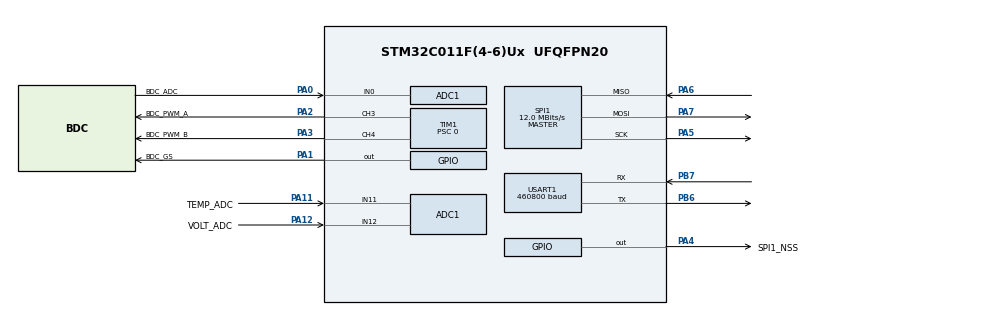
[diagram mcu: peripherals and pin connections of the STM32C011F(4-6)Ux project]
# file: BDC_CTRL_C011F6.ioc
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ADC1.Channel-0\#ChannelRegularConversion=ADC_CHANNEL_0
ADC1.Channel-1\#ChannelRegularConversion=ADC_CHANNEL_11
ADC1.Channel-2\#ChannelRegularConversion=ADC_CHANNEL_12
ADC1.ClockPrescaler=ADC_CLOCK_SYNC_PCLK_DIV2
ADC1.ContinuousConvMode=DISABLE
ADC1.DMAContinuousRequests=ENABLE
ADC1.DataAlign=ADC_DATAALIGN_RIGHT
ADC1.EOCSelection=ADC_EOC_SEQ_CONV
ADC1.ExternalTrigConv=ADC_EXTERNALTRIG_T3_TRGO
ADC1.ExternalTrigConvEdge=ADC_EXTERNALTRIGCONVEDGE_RISING
ADC1.NbrOfConversion=3
ADC1.NbrOfConversionFlag=1
ADC1.OffsetNumber-2\#ChannelRegularConversion=ADC_OFFSET_NONE
ADC1.Overrun=ADC_OVR_DATA_OVERWRITTEN
ADC1.Rank-0\#ChannelRegularConversion=1
ADC1.Rank-1\#ChannelRegularConversion=2
ADC1.Rank-2\#ChannelRegularConversion=3
ADC1.SamplingTime-0\#ChannelRegularConversion=ADC_SAMPLINGTIME_COMMON_1
ADC1.SamplingTime-1\#ChannelRegularConversion=ADC_SAMPLINGTIME_COMMON_1
ADC1.SamplingTime-2\#ChannelRegularConversion=ADC_SAMPLINGTIME_COMMON_1
ADC1.SamplingTimeCommon1=ADC_SAMPLETIME_39CYCLES_5
ADC1.SamplingTimeCommon2=ADC_SAMPLETIME_39CYCLES_5
ADC1.SelectedChannel=ADC_CHANNEL_0|ADC_CHANNEL_11|ADC_CHANNEL_12
ADC1.Sequencer=FULLY_CONFIGURABLE
ADC1.TriggerFrequencyMode=ADC_TRIGGER_FREQ_HIGH
ADC1.master=1
Dma.ADC1.0.Direction=DMA_PERIPH_TO_MEMORY
Dma.ADC1.0.EventEnable=DISABLE
Dma.ADC1.0.Instance=DMA1_Channel1
Dma.ADC1.0.MemDataAlignment=DMA_MDATAALIGN_HALFWORD
Dma.ADC1.0.MemInc=DMA_MINC_ENABLE
Dma.ADC1.0.Mode=DMA_CIRCULAR
Dma.ADC1.0.PeriphDataAlignment=DMA_PDATAALIGN_HALFWORD
Dma.ADC1.0.PeriphInc=DMA_PINC_DISABLE
Dma.ADC1.0.Polarity=HAL_DMAMUX_REQ_GEN_RISING
Dma.ADC1.0.Priority=DMA_PRIORITY_LOW
Dma.ADC1.0.RequestNumber=1
Dma.ADC1.0.SignalID=NONE
Dma.ADC1.0.SyncEnable=DISABLE
Dma.ADC1.0.SyncPolarity=HAL_DMAMUX_SYNC_NO_EVENT
Dma.ADC1.0.SyncRequestNumber=1
Dma.ADC1.0.SyncSignalID=NONE
Dma.Request0=ADC1
Dma.Request1=USART1_RX
Dma.Request2=USART1_TX
Dma.USART1_RX.1.Direction=DMA_PERIPH_TO_MEMORY
Dma.USART1_RX.1.EventEnable=DISABLE
Dma.USART1_RX.1.Instance=DMA1_Channel3
Dma.USART1_RX.1.MemDataAlignment=DMA_MDATAALIGN_BYTE
Dma.USART1_RX.1.MemInc=DMA_MINC_ENABLE
Dma.USART1_RX.1.Mode=DMA_NORMAL
Dma.USART1_RX.1.PeriphDataAlignment=DMA_PDATAALIGN_BYTE
Dma.USART1_RX.1.PeriphInc=DMA_PINC_DISABLE
Dma.USART1_RX.1.Polarity=HAL_DMAMUX_REQ_GEN_RISING
Dma.USART1_RX.1.Priority=DMA_PRIORITY_HIGH
Dma.USART1_RX.1.RequestNumber=1
Dma.USART1_RX.1.SignalID=NONE
Dma.USART1_RX.1.SyncEnable=DISABLE
Dma.USART1_RX.1.SyncPolarity=HAL_DMAMUX_SYNC_NO_EVENT
Dma.USART1_RX.1.SyncRequestNumber=1
Dma.USART1_RX.1.SyncSignalID=NONE
Dma.USART1_TX.2.Direction=DMA_MEMORY_TO_PERIPH
Dma.USART1_TX.2.EventEnable=DISABLE
Dma.USART1_TX.2.Instance=DMA1_Channel2
Dma.USART1_TX.2.MemDataAlignment=DMA_MDATAALIGN_BYTE
Dma.USART1_TX.2.MemInc=DMA_MINC_ENABLE
Dma.USART1_TX.2.Mode=DMA_NORMAL
Dma.USART1_TX.2.PeriphDataAlignment=DMA_PDATAALIGN_BYTE
Dma.USART1_TX.2.PeriphInc=DMA_PINC_DISABLE
Dma.USART1_TX.2.Polarity=HAL_DMAMUX_REQ_GEN_RISING
Dma.USART1_TX.2.Priority=DMA_PRIORITY_HIGH
Dma.USART1_TX.2.RequestNumber=1
Dma.USART1_TX.2.SignalID=NONE
Dma.USART1_TX.2.SyncEnable=DISABLE
Dma.USART1_TX.2.SyncPolarity=HAL_DMAMUX_SYNC_NO_EVENT
Dma.USART1_TX.2.SyncRequestNumber=1
Dma.USART1_TX.2.SyncSignalID=NONE
Mcu.Family=STM32C0
Mcu.Name=STM32C011F(4-6)Ux
Mcu.Package=UFQFPN20
NVIC.DMA1_Channel1_IRQn=true\:0\:0\:false\:false\:true\:false\:true\:true
NVIC.DMA1_Channel2_3_IRQn=true\:1\:0\:true\:false\:true\:false\:true\:true
NVIC.TIM16_IRQn=true\:3\:0\:true\:false\:true\:true\:true\:true
NVIC.TIM17_IRQn=true\:3\:0\:true\:false\:true\:true\:true\:true
NVIC.TIM1_BRK_UP_TRG_COM_IRQn=true\:0\:0\:false\:false\:true\:true\:true\:true
NVIC.TIM1_CC_IRQn=true\:0\:0\:false\:false\:true\:true\:true\:true
NVIC.TIM3_IRQn=true\:1\:0\:true\:false\:true\:true\:true\:true
NVIC.USART1_IRQn=true\:2\:0\:true\:false\:true\:true\:true\:true
PA0.GPIO_Label=BDC_ADC
PA0.Mode=IN0
PA0.Signal=ADC1_IN0
PA1.GPIO_Label=BDC_GS
PA1.Signal=GPIO_Output
PA11\ [PA9].GPIO_Label=TEMP_ADC
PA11\ [PA9].Mode=IN11
PA11\ [PA9].Signal=ADC1_IN11
PA12\ [PA10].GPIO_Label=VOLT_ADC
PA12\ [PA10].Mode=IN12
PA12\ [PA10].Signal=ADC1_IN12
PA13.Mode=Serial_Wire
PA13.Signal=DEBUG_SWDIO
PA14-BOOT0.Mode=Serial_Wire
PA14-BOOT0.Signal=DEBUG_SWCLK
PA2.GPIO_Label=BDC_PWM_A
PA2.PinState=GPIO_PIN_SET
PA2.Signal=S_TIM1_CH3
PA3.GPIO_Label=BDC_PWM_B
PA3.PinState=GPIO_PIN_SET
PA3.Signal=S_TIM1_CH4
PA4.GPIO_Label=SPI1_NSS
PA4.Signal=GPIO_Output
PA5.Mode=Full_Duplex_Master
PA5.Signal=SPI1_SCK
PA6.Mode=Full_Duplex_Master
PA6.Signal=SPI1_MISO
PA7.Mode=Full_Duplex_Master
PA7.Signal=SPI1_MOSI
PB6.GPIO_FM6=__NULL
PB6.GPIO_PuPd=GPIO_PULLUP
PB6.GPIO_Speed=GPIO_SPEED_FREQ_HIGH
PB6.Mode=Asynchronous
PB6.Signal=USART1_TX
PB7.GPIO_Speed=GPIO_SPEED_FREQ_HIGH
PB7.Mode=Asynchronous
PB7.Signal=USART1_RX
PC14-OSCX_IN\ (PC14).Mode=HSE-External-Clock-Source-REMAPPED
PC14-OSCX_IN\ (PC14).Signal=RCC_OSCX_IN
ProjectManager.HeapSize=0x400
ProjectManager.StackSize=0x600
ProjectManager.TargetToolchain=MDK-ARM V5.39
RCC.ADCFreq_Value=48000000
RCC.AHBFreq_Value=48000000
RCC.CortexFreq_Value=48000000
RCC.EXTERNAL_CLOCK_VALUE=12288000
RCC.HCLKFreq_Value=48000000
RCC.HSE_VALUE=48000000
RCC.HSISYSCLKDivider=RCC_HSI_DIV1
RCC.HSI_VALUE=48000000
RCC.LSE_VALUE=32768
RCC.SYSCLKFreq_VALUE=48000000
RCC.SYSCLKSource=RCC_SYSCLKSOURCE_HSE
RCC.USART1CLockSelection=RCC_USART1CLKSOURCE_SYSCLK
SH.S_TIM1_CH3.0=TIM1_CH3,PWM Generation3 CH3
SH.S_TIM1_CH4.0=TIM1_CH4,PWM Generation4 CH4
SPI1.BaudRatePrescaler=SPI_BAUDRATEPRESCALER_4
SPI1.CalculateBaudRate=12.0 MBits/s
SPI1.DataSize=SPI_DATASIZE_16BIT
SPI1.Direction=SPI_DIRECTION_2LINES
SPI1.Mode=SPI_MODE_MASTER
SPI1.VirtualType=VM_MASTER
TIM1.AutoReloadPreload=TIM_AUTORELOAD_PRELOAD_ENABLE
TIM1.Channel-PWM\ Generation3\ CH3=TIM_CHANNEL_3
TIM1.Channel-PWM\ Generation4\ CH4=TIM_CHANNEL_4
TIM1.OCMode_PWM-PWM\ Generation3\ CH3=TIM_OCMODE_PWM1
TIM1.OCMode_PWM-PWM\ Generation4\ CH4=TIM_OCMODE_PWM1
TIM1.Period=2399
TIM1.Prescaler=0
TIM1.TIM_MasterOutputTrigger=TIM_TRGO_UPDATE
TIM1.TIM_MasterOutputTrigger2=TIM_TRGO2_RESET
TIM16.AutoReloadPreload=TIM_AUTORELOAD_PRELOAD_ENABLE
TIM16.Period=499
TIM16.Prescaler=47
TIM17.AutoReloadPreload=TIM_AUTORELOAD_PRELOAD_ENABLE
TIM17.Period=9999
TIM17.Prescaler=4799
TIM3.AutoReloadPreload=TIM_AUTORELOAD_PRELOAD_ENABLE
TIM3.Channel-PWM\ Generation1\ No\ Output=TIM_CHANNEL_1
TIM3.OC1Preload_PWM=ENABLE
TIM3.OCFastMode_PWM-PWM\ Generation1\ No\ Output=TIM_OCFAST_DISABLE
TIM3.OCMode_PWM-PWM\ Generation1\ No\ Output=TIM_OCMODE_PWM2
TIM3.Period=99
TIM3.Prescaler=47
TIM3.Pulse-PWM\ Generation1\ No\ Output=0
TIM3.TIM_MasterOutputTrigger=TIM_TRGO_OC1REF
USART1.BaudRate=460800
USART1.Mode=MODE_TX_RX
USART1.VirtualMode-Asynchronous=VM_ASYNC
VP_TIM16_VS_ClockSourceINT.Mode=Enable_Timer
VP_TIM17_VS_ClockSourceINT.Mode=Enable_Timer
VP_TIM1_VS_ClockSourceINT.Mode=Internal
VP_TIM3_VS_ClockSourceINT.Mode=Internal
VP_TIM3_VS_ClockSourceITR.Mode=TriggerSource_ITR0
VP_TIM3_VS_ControllerModeTrigger.Mode=Trigger Mode
VP_TIM3_VS_no_output1.Mode=PWM Generation1 No Output
board=custom

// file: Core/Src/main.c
/* USER CODE BEGIN Header */
/**
  ******************************************************************************
  * @file           : main.c
  * @brief          : Main program body
  ******************************************************************************
  * @attention
  *
  * Copyright (c) 2025 STMicroelectronics.
  * All rights reserved.
  *
  * This software is licensed under terms that can be found in the LICENSE file
  * in the root directory of this software component.
  * If no LICENSE file comes with this software, it is provided AS-IS.
  *
  ******************************************************************************
  */
/* USER CODE END Header */
#include "main.h"
#include "adc.h"
#include "dma.h"
#include "spi.h"
#include "tim.h"
#include "usart.h"
#include "gpio.h"

/* USER CODE BEGIN Includes */
#include "bdc_motor.h"
/* USER CODE END Includes */

void SystemClock_Config(void);

/* USER CODE BEGIN 0 */
extern BDC_Motor* main_core;

/* USER CODE END 0 */

int main(void)
{

  /* MCU Configuration--------------------------------------------------------*/

  /* Reset of all peripherals, Initializes the Flash interface and the Systick. */
  HAL_Init();

  /* Configure the system clock */
  SystemClock_Config();

  /* Initialize all configured peripherals */
  MX_GPIO_Init();
  MX_DMA_Init();
  MX_ADC1_Init();
  MX_TIM1_Init();
  MX_TIM16_Init();
  MX_TIM17_Init();
  MX_SPI1_Init();
  MX_USART1_UART_Init();
  MX_TIM3_Init();
  /* USER CODE BEGIN 2 */
  main_core = new_BDC_Motor();
  BDC_Motor_Init(main_core);
  //BDC_Motor_Enable(main_core);
  /* USER CODE END 2 */

  /* Infinite loop */
  /* USER CODE BEGIN WHILE */
  while (1)
  {
    BDC_Motor_Process(main_core);

    /* USER CODE END WHILE */

  }
}

void SystemClock_Config(void)
{
  RCC_OscInitTypeDef RCC_OscInitStruct = {0};
  RCC_ClkInitTypeDef RCC_ClkInitStruct = {0};

  __HAL_FLASH_SET_LATENCY(FLASH_LATENCY_1);

  /** Initializes the RCC Oscillators according to the specified parameters
  * in the RCC_OscInitTypeDef structure.
  */
  RCC_OscInitStruct.OscillatorType = RCC_OSCILLATORTYPE_HSE;
  RCC_OscInitStruct.HSEState = RCC_HSE_BYPASS;
  if (HAL_RCC_OscConfig(&RCC_OscInitStruct) != HAL_OK)
  {
    Error_Handler();
  }

  /** Initializes the CPU, AHB and APB buses clocks
  */
  RCC_ClkInitStruct.ClockType = RCC_CLOCKTYPE_HCLK|RCC_CLOCKTYPE_SYSCLK
                              |RCC_CLOCKTYPE_PCLK1;
  RCC_ClkInitStruct.SYSCLKSource = RCC_SYSCLKSOURCE_HSE;
  RCC_ClkInitStruct.SYSCLKDivider = RCC_SYSCLK_DIV1;
  RCC_ClkInitStruct.AHBCLKDivider = RCC_HCLK_DIV1;
  RCC_ClkInitStruct.APB1CLKDivider = RCC_APB1_DIV1;

  if (HAL_RCC_ClockConfig(&RCC_ClkInitStruct, FLASH_LATENCY_1) != HAL_OK)
  {
    Error_Handler();
  }
}

void Error_Handler(void)
{
  __disable_irq();
  while (1)
  {
  }
}
